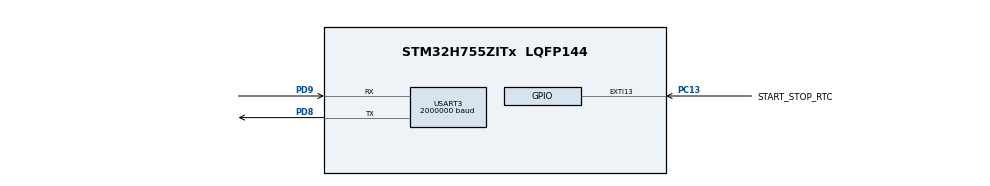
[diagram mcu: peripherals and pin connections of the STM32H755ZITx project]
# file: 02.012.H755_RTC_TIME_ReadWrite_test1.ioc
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CortexM4.IPs=FATFS_M4\:I,FREERTOS_M4\:I,IWDG2\:I,RCC,WWDG2\:I,DMA,BDMA,MDMA,NVIC2\:I,ETH,DEBUG,PDM2PCM_M4\:I,PWR,RESMGR_UTILITY,SYS_M4\:I,USB_DEVICE_M4\:I,USB_HOST_M4\:I,CORTEX_M4\:I,GPIO,OPENAMP_M4\:I,VREFBUF,NUCLEO-H755ZI-Q
CortexM7.IPs=FATFS_M7\:I,FREERTOS_M7\:I,IWDG1\:I,RCC\:I,WWDG1\:I,DMA\:I,BDMA\:I,MDMA\:I,NVIC1\:I,ETH\:I,USB_OTG_FS\:I,SYS\:I,CORTEX_M7\:I,DEBUG\:I,PDM2PCM_M7\:I,PWR\:I,RESMGR_UTILITY\:I,USB_DEVICE_M7\:I,USB_HOST_M7\:I,GPIO\:I,OPENAMP_M7\:I,VREFBUF\:I,NUCLEO-H755ZI-Q\:I,RTC\:I,USART3\:I
CortexM7.Pins=PC13
Dma.Request0=USART3_TX
Dma.Request1=USART3_RX
Dma.USART3_RX.1.Direction=DMA_PERIPH_TO_MEMORY
Dma.USART3_RX.1.EventEnable=DISABLE
Dma.USART3_RX.1.FIFOMode=DMA_FIFOMODE_DISABLE
Dma.USART3_RX.1.Instance=DMA1_Stream1
Dma.USART3_RX.1.MemDataAlignment=DMA_MDATAALIGN_BYTE
Dma.USART3_RX.1.MemInc=DMA_MINC_ENABLE
Dma.USART3_RX.1.Mode=DMA_CIRCULAR
Dma.USART3_RX.1.PeriphDataAlignment=DMA_PDATAALIGN_BYTE
Dma.USART3_RX.1.PeriphInc=DMA_PINC_DISABLE
Dma.USART3_RX.1.Polarity=HAL_DMAMUX_REQ_GEN_RISING
Dma.USART3_RX.1.Priority=DMA_PRIORITY_LOW
Dma.USART3_RX.1.RequestNumber=1
Dma.USART3_RX.1.SignalID=NONE
Dma.USART3_RX.1.SyncEnable=DISABLE
Dma.USART3_RX.1.SyncPolarity=HAL_DMAMUX_SYNC_NO_EVENT
Dma.USART3_RX.1.SyncRequestNumber=1
Dma.USART3_RX.1.SyncSignalID=NONE
Dma.USART3_TX.0.Direction=DMA_MEMORY_TO_PERIPH
Dma.USART3_TX.0.EventEnable=DISABLE
Dma.USART3_TX.0.FIFOMode=DMA_FIFOMODE_DISABLE
Dma.USART3_TX.0.Instance=DMA1_Stream0
Dma.USART3_TX.0.MemDataAlignment=DMA_MDATAALIGN_BYTE
Dma.USART3_TX.0.MemInc=DMA_MINC_ENABLE
Dma.USART3_TX.0.Mode=DMA_NORMAL
Dma.USART3_TX.0.PeriphDataAlignment=DMA_PDATAALIGN_BYTE
Dma.USART3_TX.0.PeriphInc=DMA_PINC_DISABLE
Dma.USART3_TX.0.Polarity=HAL_DMAMUX_REQ_GEN_RISING
Dma.USART3_TX.0.Priority=DMA_PRIORITY_LOW
Dma.USART3_TX.0.RequestNumber=1
Dma.USART3_TX.0.SignalID=NONE
Dma.USART3_TX.0.SyncEnable=DISABLE
Dma.USART3_TX.0.SyncPolarity=HAL_DMAMUX_SYNC_NO_EVENT
Dma.USART3_TX.0.SyncRequestNumber=1
Dma.USART3_TX.0.SyncSignalID=NONE
Mcu.Family=STM32H7
Mcu.Name=STM32H755ZITx
Mcu.Package=LQFP144
NVIC1.DMA1_Stream0_IRQn=true\:1\:0\:true\:false\:true\:false\:true\:true
NVIC1.DMA1_Stream1_IRQn=true\:1\:0\:true\:false\:true\:false\:true\:true
NVIC1.EXTI15_10_IRQn=true\:2\:0\:true\:false\:true\:true\:true\:true
NVIC1.PriorityGroup=NVIC_PRIORITYGROUP_4
NVIC1.RTC_WKUP_IRQn=true\:0\:0\:false\:false\:true\:true\:true\:true
NVIC1.USART3_IRQn=true\:1\:0\:true\:false\:true\:true\:true\:true
NVIC2.PriorityGroup=NVIC_PRIORITYGROUP_4
PC13.GPIO_Label=START_STOP_RTC
PC13.GPIO_PuPd=GPIO_PULLDOWN
PC13.PinAttribute=CortexM7
PC13.Signal=GPXTI13
PC14-OSC32_IN\ (OSC32_IN).Mode=LSE-External-Oscillator
PC14-OSC32_IN\ (OSC32_IN).PinAttribute=Free
PC14-OSC32_IN\ (OSC32_IN).Signal=RCC_OSC32_IN
PC15-OSC32_OUT\ (OSC32_OUT).Mode=LSE-External-Oscillator
PC15-OSC32_OUT\ (OSC32_OUT).PinAttribute=Free
PC15-OSC32_OUT\ (OSC32_OUT).Signal=RCC_OSC32_OUT
PD8.Mode=Asynchronous
PD8.PinAttribute=CortexM7
PD8.Signal=USART3_TX
PD8.TagName=VCP_RX
PD9.Mode=Asynchronous
PD9.PinAttribute=CortexM7
PD9.Signal=USART3_RX
PD9.TagName=VCP_TX
ProjectManager.HeapSize=M4-0x200,M7-0x200
ProjectManager.StackSize=M4-0x400,M7-0x400
ProjectManager.TargetToolchain=STM32CubeIDE
RCC.ADCFreq_Value=129000000
RCC.APB1Freq_Value=100000000
RCC.APB2Freq_Value=100000000
RCC.APB3Freq_Value=100000000
RCC.APB4Freq_Value=100000000
RCC.CortexFreq_Value=400000000
RCC.D1PPRE=RCC_APB3_DIV2
RCC.D2PPRE1=RCC_APB1_DIV2
RCC.D2PPRE2=RCC_APB2_DIV2
RCC.D3PPRE=RCC_APB4_DIV2
RCC.DIVM1=4
RCC.DIVN1=50
RCC.DIVQ1=5
RCC.HCLKFreq_Value=200000000
RCC.HPRE=RCC_HCLK_DIV2
RCC.PLL2FRACN=0
RCC.PLL3FRACN=0
RCC.PLLFRACN=0
RCC.RTCClockSelection=RCC_RTCCLKSOURCE_LSE
RCC.SYSCLKFreq_VALUE=400000000
RCC.SYSCLKSource=RCC_SYSCLKSOURCE_PLLCLK
RCC.SupplySource=PWR_DIRECT_SMPS_SUPPLY
RCC.USBFreq_Value=160000000
RTC.Format=RTC_FORMAT_BIN
RTC.WakeUpCounter-WakeUp=2047
USART3.BaudRate=2000000
USART3.VirtualMode-Asynchronous=VM_ASYNC
VP_RTC_VS_RTC_Activate.Mode=RTC_Enabled
VP_RTC_VS_RTC_Calendar.Mode=RTC_Calendar
VP_RTC_VS_RTC_WakeUp_intern.Mode=WakeUp
VP_SYS_M4_VS_Systick.Mode=SysTick
board=NUCLEO-H755ZI-Q

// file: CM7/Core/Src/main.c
/* USER CODE BEGIN Header */
/**
  ******************************************************************************
  * @file           : main.c
  * @brief          : Main program body
  ******************************************************************************
  * @attention
  *
  * Copyright (c) 2025 STMicroelectronics.
  * All rights reserved.
  *
  * This software is licensed under terms that can be found in the LICENSE file
  * in the root directory of this software component.
  * If no LICENSE file comes with this software, it is provided AS-IS.
  *
  ******************************************************************************
  */
/* USER CODE END Header */
#include "main.h"

/* USER CODE BEGIN Includes */
#include <stdio.h>
#include <string.h>
#include <stddef.h>
#include <stdarg.h>
#include <stdbool.h>
#include <stdlib.h>
/* USER CODE END Includes */

/* USER CODE BEGIN PD */

/* DUAL_CORE_BOOT_SYNC_SEQUENCE: Define for dual core boot synchronization    */
/*                             demonstration code based on hardware semaphore */
/* This define is present in both CM7/CM4 projects                            */
/* To comment when developping/debugging on a single core                     */
#define DUAL_CORE_BOOT_SYNC_SEQUENCE

#if defined(DUAL_CORE_BOOT_SYNC_SEQUENCE)
#ifndef HSEM_ID_0
#define HSEM_ID_0 (0U) /* HW semaphore 0*/
#endif
#endif /* DUAL_CORE_BOOT_SYNC_SEQUENCE */

/* USER CODE END PD */

RTC_HandleTypeDef hrtc;

UART_HandleTypeDef huart3;
DMA_HandleTypeDef hdma_usart3_tx;
DMA_HandleTypeDef hdma_usart3_rx;

/* USER CODE BEGIN PV */

uint8_t dma_rx_buffer[64];
uint8_t dma_tx_buffer[64];
uint16_t old_pos = 0;

static volatile bool uart_tx_busy = false;
static char uartBuffer[250];

#define CMD_BUFFER_SIZE 64

static char cmd_buffer[CMD_BUFFER_SIZE];
static uint8_t cmd_index = 0;

volatile uint32_t rtc_remaining_seconds = 0;

volatile bool rtc_countdown_active = false;
volatile bool is_start_button_active = false;

/* USER CODE END PV */

void SystemClock_Config(void);
static void MX_GPIO_Init(void);
static void MX_DMA_Init(void);
static void MX_RTC_Init(void);
static void MX_USART3_UART_Init(void);

/* USER CODE BEGIN 0 */

void DebugPrint(const char *format, ...)
{
	// Wait for previous transmission to complete
	    while (uart_tx_busy);

	    va_list args;
	    va_start(args, format);
	    vsnprintf(uartBuffer, sizeof(uartBuffer), format, args);
	    va_end(args);

	    uart_tx_busy = true;

	    HAL_UART_Transmit_DMA(&huart3, (uint8_t *)uartBuffer, strlen(uartBuffer));
}

void activate_RTC_IT(void)
{
	HAL_RTCEx_DeactivateWakeUpTimer(&hrtc);
	HAL_RTCEx_SetWakeUpTimer_IT(&hrtc,2047,RTC_WAKEUPCLOCK_RTCCLK_DIV16);
}

void deactivate_RTC_IT(void)
{
	HAL_RTCEx_DeactivateWakeUpTimer(&hrtc);
}

void flow_task(void)
{
    if (rtc_countdown_active && rtc_remaining_seconds == 0)
    {
        rtc_countdown_active = false;
        is_start_button_active = false;
//        motor_stop();
//        flow_controller_stop();

        DebugPrint("Therapy time elapsed → Infusion STOPPED\r\n");
        deactivate_RTC_IT();
    }
}

void RTC_SetTime_HMS(uint8_t h, uint8_t m, uint8_t s)
{
    RTC_TimeTypeDef t = {0};

    t.Hours   = h;
    t.Minutes = m;
    t.Seconds = s;
    t.DayLightSaving = RTC_DAYLIGHTSAVING_NONE;
    t.StoreOperation = RTC_STOREOPERATION_RESET;

    if (HAL_RTC_SetTime(&hrtc, &t, RTC_FORMAT_BIN) == HAL_OK)
    {
        DebugPrint("RTC SET OK -> %02d:%02d:%02d\r\n", t.Hours, t.Minutes, t.Seconds);
    }
    else
    {
        DebugPrint("RTC SET FAILED\r\n");
    }
}

void process_command(char *cmd)
{
    int hh, mm, ss;

    /* Parse HH:MM:SS */
    if (sscanf(cmd, "%d:%d:%d", &hh, &mm, &ss) == 3)
    {
        /* Range validation */
        if (hh < 0 || hh > 23 ||
            mm < 0 || mm > 59 ||
            ss < 0 || ss > 59)
        {
            DebugPrint("Invalid time range\r\n");
            return;
        }

        /* Set RTC time */
        RTC_SetTime_HMS((uint8_t)hh, (uint8_t)mm, (uint8_t)ss);

        /* Convert to total seconds */
        rtc_remaining_seconds =
            (uint32_t)hh * 3600UL +
            (uint32_t)mm * 60UL +
            (uint32_t)ss;

        DebugPrint("RTC set: %02d:%02d:%02d\r\n", hh, mm, ss);

        return;
    }

    DebugPrint("Unknown command\r\n");
}

void check_dma_data(void)
{
    uint16_t pos = sizeof(dma_rx_buffer) - __HAL_DMA_GET_COUNTER(&hdma_usart3_rx);

    while (old_pos != pos)
    {
        char c = dma_rx_buffer[old_pos];
        old_pos++;

        if (old_pos >= sizeof(dma_rx_buffer))
            old_pos = 0;

        // ENTER key handling
        if (c == '\r' || c == '\n')
        {
            if (cmd_index > 0)
            {
                cmd_buffer[cmd_index] = '\0';
                DebugPrint("\r\nCMD: %s\r\n", cmd_buffer);
                process_command(cmd_buffer);
                cmd_index = 0;
            }
        }
        else
        {
            if (cmd_index < CMD_BUFFER_SIZE - 1)
            {
                cmd_buffer[cmd_index++] = c;
            }
        }
    }
}

void rtc_get_remaining_hms(uint32_t sec,uint8_t *h,uint8_t *m,uint8_t *s)
{
    *h = sec / 3600;
    *m = (sec % 3600) / 60;
    *s = sec % 60;
}

void rtc_enable_1s_tick(void)
{
    HAL_RTCEx_DeactivateWakeUpTimer(&hrtc);

    // 1 second tick:
    // 32768 Hz / 16 = 2048
    // 2048 - 1 = 2047
    HAL_RTCEx_SetWakeUpTimer_IT(
        &hrtc,
        2047,
        RTC_WAKEUPCLOCK_RTCCLK_DIV16
    );
}

/* USER CODE END 0 */

int main(void)
{

/* USER CODE BEGIN Boot_Mode_Sequence_0 */
#if defined(DUAL_CORE_BOOT_SYNC_SEQUENCE)
  int32_t timeout;
#endif /* DUAL_CORE_BOOT_SYNC_SEQUENCE */
/* USER CODE END Boot_Mode_Sequence_0 */

/* USER CODE BEGIN Boot_Mode_Sequence_1 */
#if defined(DUAL_CORE_BOOT_SYNC_SEQUENCE)
  /* Wait until CPU2 boots and enters in stop mode or timeout*/
  timeout = 0xFFFF;
  while((__HAL_RCC_GET_FLAG(RCC_FLAG_D2CKRDY) != RESET) && (timeout-- > 0));
  if ( timeout < 0 )
  {
  Error_Handler();
  }
#endif /* DUAL_CORE_BOOT_SYNC_SEQUENCE */
/* USER CODE END Boot_Mode_Sequence_1 */
  /* MCU Configuration--------------------------------------------------------*/

  /* Reset of all peripherals, Initializes the Flash interface and the Systick. */
  HAL_Init();

  /* Configure the system clock */
  SystemClock_Config();
/* USER CODE BEGIN Boot_Mode_Sequence_2 */
#if defined(DUAL_CORE_BOOT_SYNC_SEQUENCE)
/* When system initialization is finished, Cortex-M7 will release Cortex-M4 by means of
HSEM notification */
/*HW semaphore Clock enable*/
__HAL_RCC_HSEM_CLK_ENABLE();
/*Take HSEM */
HAL_HSEM_FastTake(HSEM_ID_0);
/*Release HSEM in order to notify the CPU2(CM4)*/
HAL_HSEM_Release(HSEM_ID_0,0);
/* wait until CPU2 wakes up from stop mode */
timeout = 0xFFFF;
while((__HAL_RCC_GET_FLAG(RCC_FLAG_D2CKRDY) == RESET) && (timeout-- > 0));
if ( timeout < 0 )
{
Error_Handler();
}
#endif /* DUAL_CORE_BOOT_SYNC_SEQUENCE */
/* USER CODE END Boot_Mode_Sequence_2 */

  /* Initialize all configured peripherals */
  MX_GPIO_Init();
  MX_DMA_Init();
  MX_RTC_Init();
  MX_USART3_UART_Init();
  /* USER CODE BEGIN 2 */
  HAL_UART_Receive_DMA(&huart3, dma_rx_buffer, sizeof(dma_rx_buffer));
  DebugPrint("RTC test\n\r");

//  rtc_enable_1s_tick();
  HAL_RTCEx_DeactivateWakeUpTimer(&hrtc);
  /* USER CODE END 2 */

  /* Infinite loop */
  while (1)
  {

    /* USER CODE BEGIN 3 */
	  check_dma_data();
	  flow_task();

	  static uint32_t last_ui_sec = 0;

	  if (last_ui_sec != rtc_remaining_seconds)
	  {
		  last_ui_sec = rtc_remaining_seconds;

		  uint8_t h, m, s;

		  rtc_get_remaining_hms(last_ui_sec, &h, &m, &s);

		  DebugPrint("TIME %02d:%02d:%02d\r\n",h, m, s);
	  }

  }
  /* USER CODE END 3 */
}

void SystemClock_Config(void)
{
  RCC_OscInitTypeDef RCC_OscInitStruct = {0};
  RCC_ClkInitTypeDef RCC_ClkInitStruct = {0};

  /** Supply configuration update enable
  */
  HAL_PWREx_ConfigSupply(PWR_DIRECT_SMPS_SUPPLY);

  /** Configure the main internal regulator output voltage
  */
  __HAL_PWR_VOLTAGESCALING_CONFIG(PWR_REGULATOR_VOLTAGE_SCALE1);

  while(!__HAL_PWR_GET_FLAG(PWR_FLAG_VOSRDY)) {}

  /** Configure LSE Drive Capability
  */
  HAL_PWR_EnableBkUpAccess();
  __HAL_RCC_LSEDRIVE_CONFIG(RCC_LSEDRIVE_LOW);

  /** Initializes the RCC Oscillators according to the specified parameters
  * in the RCC_OscInitTypeDef structure.
  */
  RCC_OscInitStruct.OscillatorType = RCC_OSCILLATORTYPE_HSI|RCC_OSCILLATORTYPE_LSE;
  RCC_OscInitStruct.LSEState = RCC_LSE_ON;
  RCC_OscInitStruct.HSIState = RCC_HSI_DIV1;
  RCC_OscInitStruct.HSICalibrationValue = RCC_HSICALIBRATION_DEFAULT;
  RCC_OscInitStruct.PLL.PLLState = RCC_PLL_ON;
  RCC_OscInitStruct.PLL.PLLSource = RCC_PLLSOURCE_HSI;
  RCC_OscInitStruct.PLL.PLLM = 4;
  RCC_OscInitStruct.PLL.PLLN = 50;
  RCC_OscInitStruct.PLL.PLLP = 2;
  RCC_OscInitStruct.PLL.PLLQ = 5;
  RCC_OscInitStruct.PLL.PLLR = 2;
  RCC_OscInitStruct.PLL.PLLRGE = RCC_PLL1VCIRANGE_3;
  RCC_OscInitStruct.PLL.PLLVCOSEL = RCC_PLL1VCOWIDE;
  RCC_OscInitStruct.PLL.PLLFRACN = 0;
  if (HAL_RCC_OscConfig(&RCC_OscInitStruct) != HAL_OK)
  {
    Error_Handler();
  }

  /** Initializes the CPU, AHB and APB buses clocks
  */
  RCC_ClkInitStruct.ClockType = RCC_CLOCKTYPE_HCLK|RCC_CLOCKTYPE_SYSCLK
                              |RCC_CLOCKTYPE_PCLK1|RCC_CLOCKTYPE_PCLK2
                              |RCC_CLOCKTYPE_D3PCLK1|RCC_CLOCKTYPE_D1PCLK1;
  RCC_ClkInitStruct.SYSCLKSource = RCC_SYSCLKSOURCE_PLLCLK;
  RCC_ClkInitStruct.SYSCLKDivider = RCC_SYSCLK_DIV1;
  RCC_ClkInitStruct.AHBCLKDivider = RCC_HCLK_DIV2;
  RCC_ClkInitStruct.APB3CLKDivider = RCC_APB3_DIV2;
  RCC_ClkInitStruct.APB1CLKDivider = RCC_APB1_DIV2;
  RCC_ClkInitStruct.APB2CLKDivider = RCC_APB2_DIV2;
  RCC_ClkInitStruct.APB4CLKDivider = RCC_APB4_DIV2;

  if (HAL_RCC_ClockConfig(&RCC_ClkInitStruct, FLASH_LATENCY_2) != HAL_OK)
  {
    Error_Handler();
  }
}

static void MX_RTC_Init(void)
{

  RTC_TimeTypeDef sTime = {0};
  RTC_DateTypeDef sDate = {0};

  /** Initialize RTC Only
  */
  hrtc.Instance = RTC;
  hrtc.Init.HourFormat = RTC_HOURFORMAT_24;
  hrtc.Init.AsynchPrediv = 127;
  hrtc.Init.SynchPrediv = 255;
  hrtc.Init.OutPut = RTC_OUTPUT_DISABLE;
  hrtc.Init.OutPutPolarity = RTC_OUTPUT_POLARITY_HIGH;
  hrtc.Init.OutPutType = RTC_OUTPUT_TYPE_OPENDRAIN;
  hrtc.Init.OutPutRemap = RTC_OUTPUT_REMAP_NONE;
  if (HAL_RTC_Init(&hrtc) != HAL_OK)
  {
    Error_Handler();
  }

  /** Initialize RTC and set the Time and Date
  */
  sTime.Hours = 0;
  sTime.Minutes = 0;
  sTime.Seconds = 0;
  sTime.DayLightSaving = RTC_DAYLIGHTSAVING_NONE;
  sTime.StoreOperation = RTC_STOREOPERATION_RESET;
  if (HAL_RTC_SetTime(&hrtc, &sTime, RTC_FORMAT_BIN) != HAL_OK)
  {
    Error_Handler();
  }
  sDate.WeekDay = RTC_WEEKDAY_MONDAY;
  sDate.Month = RTC_MONTH_JANUARY;
  sDate.Date = 1;
  sDate.Year = 0;

  if (HAL_RTC_SetDate(&hrtc, &sDate, RTC_FORMAT_BIN) != HAL_OK)
  {
    Error_Handler();
  }

  /** Enable the WakeUp
  */
  if (HAL_RTCEx_SetWakeUpTimer_IT(&hrtc, 2047, RTC_WAKEUPCLOCK_RTCCLK_DIV16) != HAL_OK)
  {
    Error_Handler();
  }

}

static void MX_USART3_UART_Init(void)
{

  huart3.Instance = USART3;
  huart3.Init.BaudRate = 2000000;
  huart3.Init.WordLength = UART_WORDLENGTH_8B;
  huart3.Init.StopBits = UART_STOPBITS_1;
  huart3.Init.Parity = UART_PARITY_NONE;
  huart3.Init.Mode = UART_MODE_TX_RX;
  huart3.Init.HwFlowCtl = UART_HWCONTROL_NONE;
  huart3.Init.OverSampling = UART_OVERSAMPLING_16;
  huart3.Init.OneBitSampling = UART_ONE_BIT_SAMPLE_DISABLE;
  huart3.Init.ClockPrescaler = UART_PRESCALER_DIV1;
  huart3.AdvancedInit.AdvFeatureInit = UART_ADVFEATURE_NO_INIT;
  if (HAL_UART_Init(&huart3) != HAL_OK)
  {
    Error_Handler();
  }
  if (HAL_UARTEx_SetTxFifoThreshold(&huart3, UART_TXFIFO_THRESHOLD_1_8) != HAL_OK)
  {
    Error_Handler();
  }
  if (HAL_UARTEx_SetRxFifoThreshold(&huart3, UART_RXFIFO_THRESHOLD_1_8) != HAL_OK)
  {
    Error_Handler();
  }
  if (HAL_UARTEx_DisableFifoMode(&huart3) != HAL_OK)
  {
    Error_Handler();
  }

}

static void MX_DMA_Init(void)
{

  /* DMA controller clock enable */
  __HAL_RCC_DMA1_CLK_ENABLE();

  /* DMA interrupt init */
  /* DMA1_Stream0_IRQn interrupt configuration */
  HAL_NVIC_SetPriority(DMA1_Stream0_IRQn, 1, 0);
  HAL_NVIC_EnableIRQ(DMA1_Stream0_IRQn);
  /* DMA1_Stream1_IRQn interrupt configuration */
  HAL_NVIC_SetPriority(DMA1_Stream1_IRQn, 1, 0);
  HAL_NVIC_EnableIRQ(DMA1_Stream1_IRQn);

}

static void MX_GPIO_Init(void)
{
  GPIO_InitTypeDef GPIO_InitStruct = {0};

  /* GPIO Ports Clock Enable */
  __HAL_RCC_GPIOC_CLK_ENABLE();
  __HAL_RCC_GPIOD_CLK_ENABLE();

  /*Configure GPIO pin : START_STOP_RTC_Pin */
  GPIO_InitStruct.Pin = START_STOP_RTC_Pin;
  GPIO_InitStruct.Mode = GPIO_MODE_IT_RISING;
  GPIO_InitStruct.Pull = GPIO_PULLDOWN;
  HAL_GPIO_Init(START_STOP_RTC_GPIO_Port, &GPIO_InitStruct);

  /* EXTI interrupt init*/
  HAL_NVIC_SetPriority(START_STOP_RTC_EXTI_IRQn, 2, 0);
  HAL_NVIC_EnableIRQ(START_STOP_RTC_EXTI_IRQn);

}

/* USER CODE BEGIN 4 */
void HAL_UART_TxCpltCallback(UART_HandleTypeDef *huart)
{

    if (huart->Instance == USART3)
    {
        uart_tx_busy = false;  // Transmission complete
    }

}

void HAL_RTCEx_WakeUpTimerEventCallback(RTC_HandleTypeDef *hrtc)
{

    if (!rtc_countdown_active)
    {
    	DebugPrint("NA\r\n");
    	return;
    }

    if (rtc_remaining_seconds > 0)
    {
        rtc_remaining_seconds--;
    }

}

void HAL_GPIO_EXTI_Callback(uint16_t GPIO_Pin)
{
    if (GPIO_Pin == GPIO_PIN_13)
    {

    	is_start_button_active = !is_start_button_active;
    	if(is_start_button_active)
    	{
    		rtc_countdown_active = true;
    		DebugPrint("START\r\n");
    		activate_RTC_IT();
    	}
    	else
    	{
    		DebugPrint("PAUSE\r\n");
    		deactivate_RTC_IT();
    		rtc_countdown_active = false;
    	}

    }
}
/* USER CODE END 4 */

void Error_Handler(void)
{
  __disable_irq();
  while (1)
  {
  }
}
